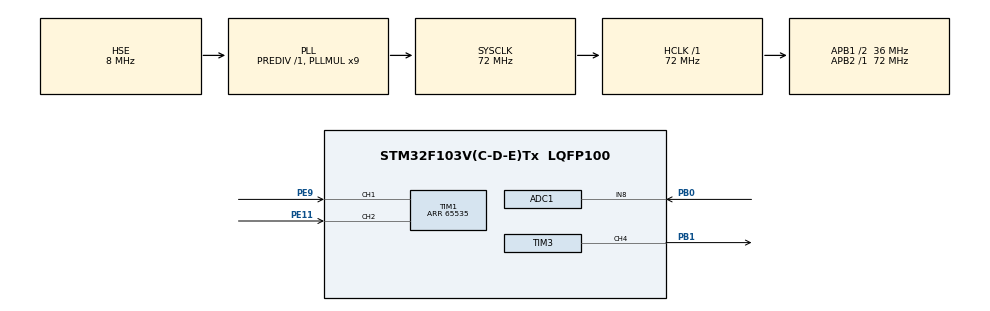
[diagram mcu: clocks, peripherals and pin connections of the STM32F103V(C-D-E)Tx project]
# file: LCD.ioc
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ADC1.Channel-0\#ChannelRegularConversion=ADC_CHANNEL_8
ADC1.ContinuousConvMode=ENABLE
ADC1.NbrOfConversion=1
ADC1.NbrOfConversionFlag=1
ADC1.Rank-0\#ChannelRegularConversion=1
ADC1.SamplingTime-0\#ChannelRegularConversion=ADC_SAMPLETIME_239CYCLES_5
ADC1.master=1
Dma.ADC1.0.Direction=DMA_PERIPH_TO_MEMORY
Dma.ADC1.0.Instance=DMA1_Channel1
Dma.ADC1.0.MemDataAlignment=DMA_MDATAALIGN_HALFWORD
Dma.ADC1.0.MemInc=DMA_MINC_ENABLE
Dma.ADC1.0.Mode=DMA_CIRCULAR
Dma.ADC1.0.PeriphDataAlignment=DMA_PDATAALIGN_HALFWORD
Dma.ADC1.0.PeriphInc=DMA_PINC_DISABLE
Dma.ADC1.0.Priority=DMA_PRIORITY_LOW
Dma.Request0=ADC1
Mcu.Family=STM32F1
Mcu.Name=STM32F103V(C-D-E)Tx
Mcu.Package=LQFP100
NVIC.DMA1_Channel1_IRQn=true\:0\:0\:false\:false\:true\:false\:true
NVIC.PriorityGroup=NVIC_PRIORITYGROUP_4
OSC_IN.Mode=HSE-External-Oscillator
OSC_IN.Signal=RCC_OSC_IN
OSC_OUT.Mode=HSE-External-Oscillator
OSC_OUT.Signal=RCC_OSC_OUT
PA13.Mode=Serial_Wire
PA13.Signal=SYS_JTMS-SWDIO
PA14.Mode=Serial_Wire
PA14.Signal=SYS_JTCK-SWCLK
PB0.Signal=ADCx_IN8
PB1.Signal=S_TIM3_CH4
PE11.Signal=S_TIM1_CH2
PE9.Signal=S_TIM1_CH1
ProjectManager.HeapSize=0x200
ProjectManager.StackSize=0x400
ProjectManager.TargetToolchain=STM32CubeIDE
RCC.ADCPresc=RCC_ADCPCLK2_DIV6
RCC.AHBFreq_Value=72000000
RCC.APB1CLKDivider=RCC_HCLK_DIV2
RCC.APB1Freq_Value=36000000
RCC.APB1TimFreq_Value=72000000
RCC.APB2Freq_Value=72000000
RCC.APB2TimFreq_Value=72000000
RCC.HCLKFreq_Value=72000000
RCC.PLLMUL=RCC_PLL_MUL9
RCC.PLLSourceVirtual=RCC_PLLSOURCE_HSE
RCC.SYSCLKFreq_VALUE=72000000
RCC.SYSCLKSource=RCC_SYSCLKSOURCE_PLLCLK
RCC.USBFreq_Value=72000000
SH.ADCx_IN8.0=ADC1_IN8,IN8
SH.S_TIM1_CH1.0=TIM1_CH1,Encoder_Interface
SH.S_TIM1_CH2.0=TIM1_CH2,Encoder_Interface
SH.S_TIM3_CH4.0=TIM3_CH4,PWM Generation4 CH4
TIM1.IC1Filter=15
TIM1.IC2Filter=15
TIM1.Period=65535
TIM3.Channel-PWM\ Generation4\ CH4=TIM_CHANNEL_4
TIM3.Period=4095
TIM3.Prescaler=17
TIM3.Pulse-PWM\ Generation4\ CH4=1000
board=custom

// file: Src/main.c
/* USER CODE BEGIN Header */
/**
  ******************************************************************************
  * @file           : main.c
  * @brief          : Main program body
  ******************************************************************************
  * @attention
  *
  * <h2><center>&copy; Copyright (c) 2020 STMicroelectronics.
  * All rights reserved.</center></h2>
  *
  * This software component is licensed by ST under BSD 3-Clause license,
  * the "License"; You may not use this file except in compliance with the
  * License. You may obtain a copy of the License at:
  *                        opensource.org/licenses/BSD-3-Clause
  *
  ******************************************************************************
  */
/* USER CODE END Header */

#include "main.h"

ADC_HandleTypeDef hadc1;
DMA_HandleTypeDef hdma_adc1;

TIM_HandleTypeDef htim1;
TIM_HandleTypeDef htim3;

/* USER CODE BEGIN PV */
uint16_t counter = 0;
uint16_t odczyt = 0;

/* USER CODE END PV */

void SystemClock_Config(void);
static void MX_GPIO_Init(void);
static void MX_DMA_Init(void);
static void MX_TIM3_Init(void);
static void MX_ADC1_Init(void);
static void MX_TIM1_Init(void);

int main(void)
{

  /* MCU Configuration--------------------------------------------------------*/

  /* Reset of all peripherals, Initializes the Flash interface and the Systick. */
  HAL_Init();

  /* Configure the system clock */
  SystemClock_Config();

  /* Initialize all configured peripherals */
  MX_GPIO_Init();
  MX_DMA_Init();
  MX_TIM3_Init();
  MX_ADC1_Init();
  MX_TIM1_Init();
  /* USER CODE BEGIN 2 */
  while(HAL_ADCEx_Calibration_Start(&hadc1) != HAL_OK);

  HAL_TIM_PWM_Start(&htim3, TIM_CHANNEL_4);
  HAL_ADC_Start_DMA(&hadc1, &odczyt, 1);

  /* USER CODE END 2 */

  /* Infinite loop */
  /* USER CODE BEGIN WHILE */
  while (1)
  {
	  TIM3->CCR4 = odczyt;
    /* USER CODE END WHILE */

  }
}

void SystemClock_Config(void)
{
  RCC_OscInitTypeDef RCC_OscInitStruct = {0};
  RCC_ClkInitTypeDef RCC_ClkInitStruct = {0};
  RCC_PeriphCLKInitTypeDef PeriphClkInit = {0};

  /** Initializes the CPU, AHB and APB busses clocks
  */
  RCC_OscInitStruct.OscillatorType = RCC_OSCILLATORTYPE_HSE;
  RCC_OscInitStruct.HSEState = RCC_HSE_ON;
  RCC_OscInitStruct.HSEPredivValue = RCC_HSE_PREDIV_DIV1;
  RCC_OscInitStruct.HSIState = RCC_HSI_ON;
  RCC_OscInitStruct.PLL.PLLState = RCC_PLL_ON;
  RCC_OscInitStruct.PLL.PLLSource = RCC_PLLSOURCE_HSE;
  RCC_OscInitStruct.PLL.PLLMUL = RCC_PLL_MUL9;
  if (HAL_RCC_OscConfig(&RCC_OscInitStruct) != HAL_OK)
  {
    Error_Handler();
  }
  /** Initializes the CPU, AHB and APB busses clocks
  */
  RCC_ClkInitStruct.ClockType = RCC_CLOCKTYPE_HCLK|RCC_CLOCKTYPE_SYSCLK
                              |RCC_CLOCKTYPE_PCLK1|RCC_CLOCKTYPE_PCLK2;
  RCC_ClkInitStruct.SYSCLKSource = RCC_SYSCLKSOURCE_PLLCLK;
  RCC_ClkInitStruct.AHBCLKDivider = RCC_SYSCLK_DIV1;
  RCC_ClkInitStruct.APB1CLKDivider = RCC_HCLK_DIV2;
  RCC_ClkInitStruct.APB2CLKDivider = RCC_HCLK_DIV1;

  if (HAL_RCC_ClockConfig(&RCC_ClkInitStruct, FLASH_LATENCY_2) != HAL_OK)
  {
    Error_Handler();
  }
  PeriphClkInit.PeriphClockSelection = RCC_PERIPHCLK_ADC;
  PeriphClkInit.AdcClockSelection = RCC_ADCPCLK2_DIV6;
  if (HAL_RCCEx_PeriphCLKConfig(&PeriphClkInit) != HAL_OK)
  {
    Error_Handler();
  }
}

static void MX_ADC1_Init(void)
{

  ADC_ChannelConfTypeDef sConfig = {0};

  /** Common config
  */
  hadc1.Instance = ADC1;
  hadc1.Init.ScanConvMode = ADC_SCAN_DISABLE;
  hadc1.Init.ContinuousConvMode = ENABLE;
  hadc1.Init.DiscontinuousConvMode = DISABLE;
  hadc1.Init.ExternalTrigConv = ADC_SOFTWARE_START;
  hadc1.Init.DataAlign = ADC_DATAALIGN_RIGHT;
  hadc1.Init.NbrOfConversion = 1;
  if (HAL_ADC_Init(&hadc1) != HAL_OK)
  {
    Error_Handler();
  }
  /** Configure Regular Channel
  */
  sConfig.Channel = ADC_CHANNEL_8;
  sConfig.Rank = ADC_REGULAR_RANK_1;
  sConfig.SamplingTime = ADC_SAMPLETIME_239CYCLES_5;
  if (HAL_ADC_ConfigChannel(&hadc1, &sConfig) != HAL_OK)
  {
    Error_Handler();
  }

}

static void MX_TIM1_Init(void)
{

  TIM_Encoder_InitTypeDef sConfig = {0};
  TIM_MasterConfigTypeDef sMasterConfig = {0};

  htim1.Instance = TIM1;
  htim1.Init.Prescaler = 0;
  htim1.Init.CounterMode = TIM_COUNTERMODE_UP;
  htim1.Init.Period = 65535;
  htim1.Init.ClockDivision = TIM_CLOCKDIVISION_DIV1;
  htim1.Init.RepetitionCounter = 0;
  htim1.Init.AutoReloadPreload = TIM_AUTORELOAD_PRELOAD_DISABLE;
  sConfig.EncoderMode = TIM_ENCODERMODE_TI1;
  sConfig.IC1Polarity = TIM_ICPOLARITY_RISING;
  sConfig.IC1Selection = TIM_ICSELECTION_DIRECTTI;
  sConfig.IC1Prescaler = TIM_ICPSC_DIV1;
  sConfig.IC1Filter = 15;
  sConfig.IC2Polarity = TIM_ICPOLARITY_RISING;
  sConfig.IC2Selection = TIM_ICSELECTION_DIRECTTI;
  sConfig.IC2Prescaler = TIM_ICPSC_DIV1;
  sConfig.IC2Filter = 15;
  if (HAL_TIM_Encoder_Init(&htim1, &sConfig) != HAL_OK)
  {
    Error_Handler();
  }
  sMasterConfig.MasterOutputTrigger = TIM_TRGO_RESET;
  sMasterConfig.MasterSlaveMode = TIM_MASTERSLAVEMODE_DISABLE;
  if (HAL_TIMEx_MasterConfigSynchronization(&htim1, &sMasterConfig) != HAL_OK)
  {
    Error_Handler();
  }

}

static void MX_TIM3_Init(void)
{

  TIM_MasterConfigTypeDef sMasterConfig = {0};
  TIM_OC_InitTypeDef sConfigOC = {0};

  htim3.Instance = TIM3;
  htim3.Init.Prescaler = 17;
  htim3.Init.CounterMode = TIM_COUNTERMODE_UP;
  htim3.Init.Period = 4095;
  htim3.Init.ClockDivision = TIM_CLOCKDIVISION_DIV1;
  htim3.Init.AutoReloadPreload = TIM_AUTORELOAD_PRELOAD_DISABLE;
  if (HAL_TIM_PWM_Init(&htim3) != HAL_OK)
  {
    Error_Handler();
  }
  sMasterConfig.MasterOutputTrigger = TIM_TRGO_RESET;
  sMasterConfig.MasterSlaveMode = TIM_MASTERSLAVEMODE_DISABLE;
  if (HAL_TIMEx_MasterConfigSynchronization(&htim3, &sMasterConfig) != HAL_OK)
  {
    Error_Handler();
  }
  sConfigOC.OCMode = TIM_OCMODE_PWM1;
  sConfigOC.Pulse = 1000;
  sConfigOC.OCPolarity = TIM_OCPOLARITY_HIGH;
  sConfigOC.OCFastMode = TIM_OCFAST_DISABLE;
  if (HAL_TIM_PWM_ConfigChannel(&htim3, &sConfigOC, TIM_CHANNEL_4) != HAL_OK)
  {
    Error_Handler();
  }
  HAL_TIM_MspPostInit(&htim3);

}

static void MX_DMA_Init(void)
{

  /* DMA controller clock enable */
  __HAL_RCC_DMA1_CLK_ENABLE();

  /* DMA interrupt init */
  /* DMA1_Channel1_IRQn interrupt configuration */
  HAL_NVIC_SetPriority(DMA1_Channel1_IRQn, 0, 0);
  HAL_NVIC_EnableIRQ(DMA1_Channel1_IRQn);

}

static void MX_GPIO_Init(void)
{

  /* GPIO Ports Clock Enable */
  __HAL_RCC_GPIOB_CLK_ENABLE();
  __HAL_RCC_GPIOE_CLK_ENABLE();
  __HAL_RCC_GPIOA_CLK_ENABLE();

}

void Error_Handler(void)
{
}

/************************ (C) COPYRIGHT STMicroelectronics *****END OF FILE****/
